VERSION ""
NS_ :

BS_:
BU_: Vector__XXX

BO_ 1296 BAR_Alarm: 8 Vector__XXX
 SG_ BRA_Rack_Num : 0|16@1+ (1.0,0) [0.0|10.0] "R" Vector__XXX
 SG_ BRA_RackNum_Alarm_OC : 16|1@1+ (1.0,0) [0.0|1.0] "F" Vector__XXX
 SG_ BRA_RackNum_Alarm_SOC_OV : 17|1@1+ (1.0,0) [0.0|1.0] "F" Vector__XXX
 SG_ BRA_RackNum_Alarm_SOC_UN : 18|1@1+ (1.0,0) [0.0|1.0] "F" Vector__XXX
 SG_ BRA_RackNum_Alarm_OV : 19|1@1+ (1.0,0) [0.0|1.0] "F" Vector__XXX
 SG_ BRA_RackNum_Alarm_UV : 20|1@1+ (1.0,0) [0.0|1.0] "F" Vector__XXX
 SG_ BRA_RackNum_Alarm_Cell_OV : 21|1@1+ (1.0,0) [0.0|1.0] "F" Vector__XXX
 SG_ BRA_RackNum_Alarm__Cell_UV : 22|1@1+ (1.0,0) [0.0|1.0] "F" Vector__XXX
 SG_ BRA_RackNum_Alarm_Cell_UnBalaV : 23|1@1+ (1.0,0) [0.0|1.0] "F" Vector__XXX
 SG_ BRA_RackNum_Alarm_Discharger_Cell_OT : 24|1@1+ (1.0,0) [0.0|1.0] "F" Vector__XXX
 SG_ BRA_RackNum_Alarm_Charger_Cell_OT : 25|1@1+ (1.0,0) [0.0|1.0] "F" Vector__XXX
 SG_ BRA_RackNum_Alarm_Charger_Cell_UT : 26|1@1+ (1.0,0) [0.0|1.0] "F" Vector__XXX
 SG_ BRA_RackNum_Alarm_Charger_Cell_UT : 27|1@1+ (1.0,0) [0.0|1.0] "F" Vector__XXX
 SG_ BRA_RackNum_Alarm_Cell_UnBalaT : 28|1@1+ (1.0,0) [0.0|1.0] "F" Vector__XXX
 SG_ BRA_RackNum_Alarm_Continuously_OP : 29|1@1+ (1.0,0) [0.0|1.0] "F" Vector__XXX
 SG_ BRA_RackNum_Alarm_Peak_OP : 30|1@1+ (1.0,0) [0.0|1.0] "F" Vector__XXX
 SG_ BRA_RackNum_Fault_OC : 32|1@1+ (1.0,0) [0.0|1.0] "F" Vector__XXX
 SG_ BRA_RackNum_Fault_SOC_OV : 33|1@1+ (1.0,0) [0.0|1.0] "F" Vector__XXX
 SG_ BRA_RackNum_Fault_SOC_UN : 34|1@1+ (1.0,0) [0.0|1.0] "F" Vector__XXX
 SG_ BRA_RackNum_Fault_OV : 35|1@1+ (1.0,0) [0.0|1.0] "F" Vector__XXX
 SG_ BRA_RackNum_Fault_UV : 36|1@1+ (1.0,0) [0.0|1.0] "F" Vector__XXX
 SG_ BRA_RackNum_Fault_Cell_OV : 37|1@1+ (1.0,0) [0.0|1.0] "F" Vector__XXX
 SG_ BRA_RackNum_Fault__Cell_UV : 38|1@1+ (1.0,0) [0.0|1.0] "F" Vector__XXX
 SG_ BRA_RackNum_Fault_Cell_UnBalaV : 39|1@1+ (1.0,0) [0.0|1.0] "F" Vector__XXX
 SG_ BRA_RackNum_Fault_Discharger_Cell_OT : 40|1@1+ (1.0,0) [0.0|1.0] "F" Vector__XXX
 SG_ BRA_RackNum_Fault_Charger_Cell_OT : 41|1@1+ (1.0,0) [0.0|1.0] "F" Vector__XXX
 SG_ BRA_RackNum_Fault_Charger_Cell_UT : 42|1@1+ (1.0,0) [0.0|1.0] "F" Vector__XXX
 SG_ BRA_RackNum_Fault_Charger_Cell_UT : 43|1@1+ (1.0,0) [0.0|1.0] "F" Vector__XXX
 SG_ BRA_RackNum_Fault_Cell_UnBalaT : 44|1@1+ (1.0,0) [0.0|1.0] "F" Vector__XXX
 SG_ BRA_RackNum_Fault_Continuously_OP : 45|1@1+ (1.0,0) [0.0|1.0] "F" Vector__XXX
 SG_ BRA_RackNum_Fault_Peak_OP : 46|1@1+ (1.0,0) [0.0|1.0] "F" Vector__XXX

BO_ 1298 BAR_DIO: 8 Vector__XXX
 SG_ BRA_Rack_Num : 0|16@1+ (1.0,0) [0.0|10.0] "R" Vector__XXX
 SG_ BRA_RackNum_Prelay_DO_Status : 16|1@1+ (1.0,0) [0.0|1.0] "F" Vector__XXX
 SG_ BRA_RackNum_Nrelay_DO_Status : 17|1@1+ (1.0,0) [0.0|1.0] "F" Vector__XXX
 SG_ BRA_RackNum_ProRelay_DO_Status : 18|1@1+ (1.0,0) [0.0|1.0] "F" Vector__XXX
 SG_ BRA_RackNum_PowerLamp_DO_Status : 19|1@1+ (1.0,0) [0.0|1.0] "F" Vector__XXX
 SG_ BRA_RackNum_Buzzer_DO_Status : 20|1@1+ (1.0,0) [0.0|1.0] "F" Vector__XXX
 SG_ BRA_RackNum_PRelayAUX_DI_Status : 32|1@1+ (1.0,0) [0.0|1.0] "F" Vector__XXX
 SG_ BRA_RackNum_NRelayAUX_DI_Status : 33|1@1+ (1.0,0) [0.0|1.0] "F" Vector__XXX
 SG_ BRA_RackNum_EMGSwitch_DI_Status : 34|1@1+ (1.0,0) [0.0|1.0] "F" Vector__XXX
 SG_ BRA_RackNum_MDS_DI_Status : 35|1@1+ (1.0,0) [0.0|1.0] "F" Vector__XXX
 SG_ BRA_RackNum_Waterleak_Dete_MD1 : 48|1@1+ (1.0,0) [0.0|1.0] "F" Vector__XXX
 SG_ BRA_RackNum_Waterleak_Dete_MD2 : 49|1@1+ (1.0,0) [0.0|1.0] "F" Vector__XXX
 SG_ BRA_RackNum_Waterleak_Dete_MD3 : 50|1@1+ (1.0,0) [0.0|1.0] "F" Vector__XXX
 SG_ BRA_RackNum_Waterleak_Dete_MD4 : 51|1@1+ (1.0,0) [0.0|1.0] "F" Vector__XXX
 SG_ BRA_RackNum_Waterleak_Dete_MD5 : 52|1@1+ (1.0,0) [0.0|1.0] "F" Vector__XXX
 SG_ BRA_RackNum_Waterleak_Dete_MD6 : 53|1@1+ (1.0,0) [0.0|1.0] "F" Vector__XXX
 SG_ BRA_RackNum_Waterleak_Dete_MD7 : 54|1@1+ (1.0,0) [0.0|1.0] "F" Vector__XXX

BO_ 1297 BAR_Protect: 8 Vector__XXX
 SG_ BRA_Rack_Num : 0|16@1+ (1.0,0) [0.0|10.0] "R" Vector__XXX
 SG_ BRA_RackNum_Prtct_OC : 16|1@1+ (1.0,0) [0.0|1.0] "F" Vector__XXX
 SG_ BRA_RackNum_Prtct_SOC_OV : 17|1@1+ (1.0,0) [0.0|1.0] "F" Vector__XXX
 SG_ BRA_RackNum_Prtct_SOC_UN : 18|1@1+ (1.0,0) [0.0|1.0] "F" Vector__XXX
 SG_ BRA_RackNum_Prtct_OV : 19|1@1+ (1.0,0) [0.0|1.0] "F" Vector__XXX
 SG_ BRA_RackNum_Prtct_UV : 20|1@1+ (1.0,0) [0.0|1.0] "F" Vector__XXX
 SG_ BRA_RackNum_Prtct_Cell_OV : 21|1@1+ (1.0,0) [0.0|1.0] "F" Vector__XXX
 SG_ BRA_RackNum_Prtct__Cell_UV : 22|1@1+ (1.0,0) [0.0|1.0] "F" Vector__XXX
 SG_ BRA_RackNum_Prtct_Cell_UnBalaV : 23|1@1+ (1.0,0) [0.0|1.0] "F" Vector__XXX
 SG_ BRA_RackNum_Prtct_Discharger_Cell_OT : 24|1@1+ (1.0,0) [0.0|1.0] "F" Vector__XXX
 SG_ BRA_RackNum_Prtct_Charger_Cell_OT : 25|1@1+ (1.0,0) [0.0|1.0] "F" Vector__XXX
 SG_ BRA_RackNum_Prtct_Charger_Cell_UT : 26|1@1+ (1.0,0) [0.0|1.0] "F" Vector__XXX
 SG_ BRA_RackNum_Prtct_Charger_Cell_UT : 27|1@1+ (1.0,0) [0.0|1.0] "F" Vector__XXX
 SG_ BRA_RackNum_Prtct_Cell_UnBalaT : 28|1@1+ (1.0,0) [0.0|1.0] "F" Vector__XXX
 SG_ BRA_RackNum_Prtct_Continuously_OP : 29|1@1+ (1.0,0) [0.0|1.0] "F" Vector__XXX
 SG_ BRA_RackNum_Prtct_Peak_OP : 30|1@1+ (1.0,0) [0.0|1.0] "F" Vector__XXX
 SG_ BRA_RackNum_Prtct_InternalCOM : 31|1@1+ (1.0,0) [0.0|1.0] "F" Vector__XXX
 SG_ BRA_RackNum_Prtct_ExternalCOM : 32|1@1+ (1.0,0) [0.0|1.0] "F" Vector__XXX
 SG_ BRA_RackNum_Prtct_RelayWelding : 33|1@1+ (1.0,0) [0.0|1.0] "F" Vector__XXX
 SG_ BRA_RackNum_Prtct_WaterLeak : 34|1@1+ (1.0,0) [0.0|1.0] "F" Vector__XXX
 SG_ BRA_RackNum_Prtct_InsulationReg : 35|1@1+ (1.0,0) [0.0|1.0] "F" Vector__XXX
 SG_ BRA_RackNum_Prtct_MDSFuse : 36|1@1+ (1.0,0) [0.0|1.0] "F" Vector__XXX
 SG_ BRA_RackNum_Prtct_CoolingSystem : 37|1@1+ (1.0,0) [0.0|1.0] "F" Vector__XXX

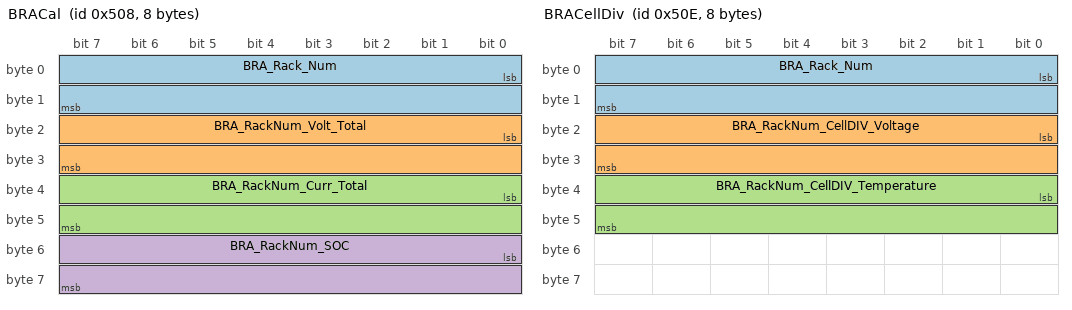
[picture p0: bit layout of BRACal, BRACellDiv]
BO_ 1288 BRACal: 8 Vector__XXX
 SG_ BRA_Rack_Num : 0|16@1+ (1.0,0) [0.0|10.0] "R" Vector__XXX
 SG_ BRA_RackNum_Volt_Total : 16|16@1+ (0.1,0) [400.0|800.0] "V" Vector__XXX
 SG_ BRA_RackNum_Curr_Total : 32|16@1- (0.1,0) [-500.0|500.0] "A" Vector__XXX
 SG_ BRA_RackNum_SOC : 48|16@1+ (0.1,0) [0.0|100.0] "%" Vector__XXX

BO_ 1294 BRACellDiv: 8 Vector__XXX
 SG_ BRA_Rack_Num : 0|16@1+ (1.0,0) [0.0|10.0] "R" Vector__XXX
 SG_ BRA_RackNum_CellDIV_Voltage : 16|16@1+ (1.0,0) [0.0|1000.0] "mV" Vector__XXX
 SG_ BRA_RackNum_CellDIV_Temperature : 32|16@1+ (0.1,0) [0.0|25.0] "℃" Vector__XXX

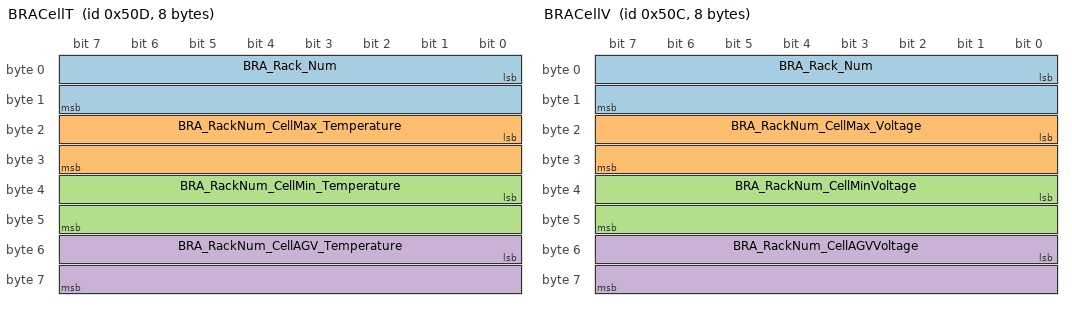
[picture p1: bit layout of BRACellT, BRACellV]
BO_ 1293 BRACellT: 8 Vector__XXX
 SG_ BRA_Rack_Num : 0|16@1+ (1.0,0) [0.0|10.0] "R" Vector__XXX
 SG_ BRA_RackNum_CellMax_Temperature : 16|16@1- (0.1,0) [-40.0|100.0] "℃" Vector__XXX
 SG_ BRA_RackNum_CellMin_Temperature : 32|16@1- (0.1,0) [-40.0|100.0] "℃" Vector__XXX
 SG_ BRA_RackNum_CellAGV_Temperature : 48|16@1- (0.1,0) [-40.0|100.0] "℃" Vector__XXX

BO_ 1292 BRACellV: 8 Vector__XXX
 SG_ BRA_Rack_Num : 0|16@1+ (1.0,0) [0.0|10.0] "R" Vector__XXX
 SG_ BRA_RackNum_CellMax_Voltage : 16|16@1+ (0.001,0) [2.8|4.5] "V" Vector__XXX
 SG_ BRA_RackNum_CellMinVoltage : 32|16@1+ (0.001,0) [2.8|4.5] "V" Vector__XXX
 SG_ BRA_RackNum_CellAGVVoltage : 48|16@1+ (0.001,0) [2.8|4.5] "V" Vector__XXX

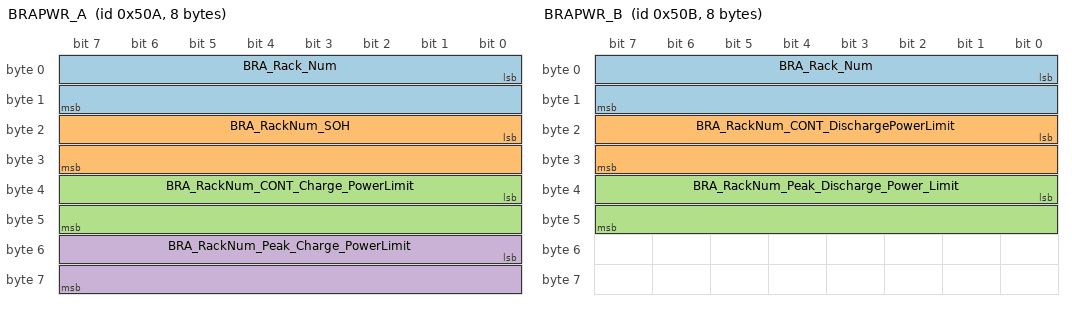
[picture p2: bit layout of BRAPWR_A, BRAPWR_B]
BO_ 1290 BRAPWR_A: 8 Vector__XXX
 SG_ BRA_Rack_Num : 0|16@1+ (1.0,0) [0.0|10.0] "R" Vector__XXX
 SG_ BRA_RackNum_SOH : 16|16@1+ (0.1,0) [0.0|100.0] "%" Vector__XXX
 SG_ BRA_RackNum_CONT_Charge_PowerLimit : 32|16@1+ (0.1,0) [0.0|200.0] "kW" Vector__XXX
 SG_ BRA_RackNum_Peak_Charge_PowerLimit : 48|16@1+ (0.1,0) [0.0|300.0] "kW" Vector__XXX

BO_ 1291 BRAPWR_B: 8 Vector__XXX
 SG_ BRA_Rack_Num : 0|16@1+ (1.0,0) [0.0|10.0] "" Vector__XXX
 SG_ BRA_RackNum_CONT_DischargePowerLimit : 16|16@1+ (0.1,0) [0.0|600.0] "kW" Vector__XXX
 SG_ BRA_RackNum_Peak_Discharge_Power_Limit : 32|16@1+ (0.1,0) [0.0|800.0] "kW" Vector__XXX

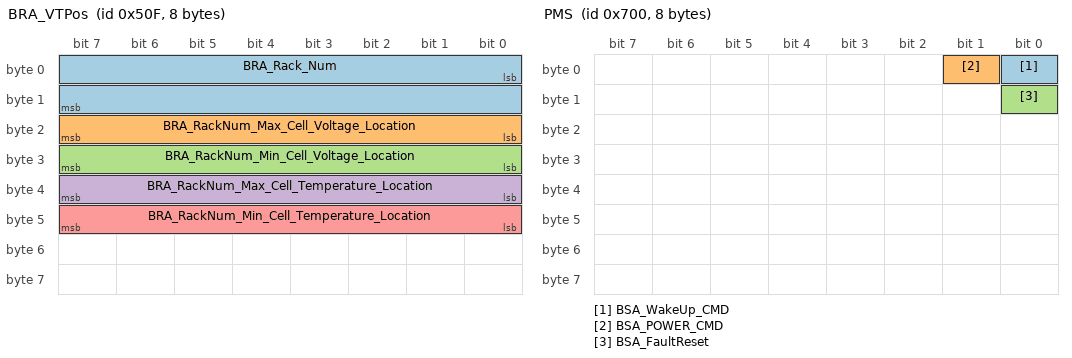
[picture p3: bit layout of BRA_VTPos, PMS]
BO_ 1295 BRA_VTPos: 8 Vector__XXX
 SG_ BRA_Rack_Num : 0|16@1+ (1.0,0) [0.0|10.0] "R" Vector__XXX
 SG_ BRA_RackNum_Max_Cell_Voltage_Location : 16|8@1+ (1.0,0) [0.0|288.0] "C" Vector__XXX
 SG_ BRA_RackNum_Min_Cell_Voltage_Location : 24|8@1+ (1.0,0) [0.0|288.0] "C" Vector__XXX
 SG_ BRA_RackNum_Max_Cell_Temperature_Location : 32|8@1+ (1.0,0) [0.0|288.0] "C" Vector__XXX
 SG_ BRA_RackNum_Min_Cell_Temperature_Location : 40|8@1+ (1.0,0) [0.0|288.0] "C" Vector__XXX

BO_ 1792 PMS: 8 Vector__XXX
 SG_ BSA_WakeUp_CMD : 0|1@1+ (1.0,0) [0.0|1.0] "F" Vector__XXX
 SG_ BSA_POWER_CMD : 1|1@1+ (1.0,0) [0.0|1.0] "F" Vector__XXX
 SG_ BSA_FaultReset : 8|1@1+ (1.0,0) [0.0|1.0] "F" Vector__XXX

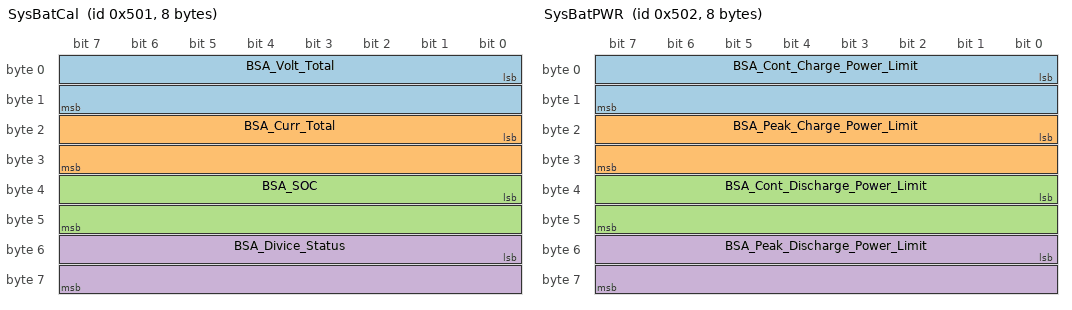
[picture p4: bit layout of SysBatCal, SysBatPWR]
BO_ 1281 SysBatCal: 8 Vector__XXX
 SG_ BSA_Volt_Total : 0|16@1+ (0.1,0) [400.0|800.0] "V" Vector__XXX
 SG_ BSA_Curr_Total : 16|16@1- (0.1,0) [-500.0|500.0] "A" Vector__XXX
 SG_ BSA_SOC : 32|16@1+ (0.1,0) [0.0|100.0] "%" Vector__XXX
 SG_ BSA_Divice_Status : 48|16@1+ (1.0,0) [0.0|10.0] "S" Vector__XXX

BO_ 1287 SysBatDIO: 8 Vector__XXX
 SG_ BSA_Prelay_DO_Status : 0|1@1+ (1.0,0) [0.0|1.0] "F" Vector__XXX
 SG_ BSA_Nrelay_DO_Status : 1|1@1+ (1.0,0) [0.0|1.0] "F" Vector__XXX
 SG_ BSA_ProRelay_DO_Status : 2|1@1+ (1.0,0) [0.0|1.0] "F" Vector__XXX
 SG_ BSA_Buzzer_DO_Status : 3|1@1+ (1.0,0) [0.0|1.0] "F" Vector__XXX
 SG_ BSA_PowerLamp_DO_Status : 4|1@1+ (1.0,0) [0.0|1.0] "F" Vector__XXX
 SG_ BSA_DO_Spare06 : 5|1@1+ (1.0,0) [0.0|1.0] "F" Vector__XXX
 SG_ BSA_DO_Spare07 : 6|1@1+ (1.0,0) [0.0|1.0] "F" Vector__XXX
 SG_ BSA_DO_Spare08 : 7|1@1+ (1.0,0) [0.0|1.0] "F" Vector__XXX
 SG_ BSA_DO_Spare09 : 8|1@1+ (1.0,0) [0.0|1.0] "F" Vector__XXX
 SG_ BSA_DO_Spare10 : 9|1@1+ (1.0,0) [0.0|1.0] "F" Vector__XXX
 SG_ BSA_DO_Spare11 : 10|1@1+ (1.0,0) [0.0|1.0] "F" Vector__XXX
 SG_ BSA_DO_Spare12 : 11|1@1+ (1.0,0) [0.0|1.0] "F" Vector__XXX
 SG_ BSA_PRelayAUX_DI_Status : 12|1@1+ (1.0,0) [0.0|1.0] "F" Vector__XXX
 SG_ BSA_NRelayAUX_DI_Status : 13|1@1+ (1.0,0) [0.0|1.0] "F" Vector__XXX
 SG_ BSA_EMGSwitch_DI_Status : 14|1@1+ (1.0,0) [0.0|1.0] "F" Vector__XXX
 SG_ BSA_CoolingSystem_DI_Status : 15|1@1+ (1.0,0) [0.0|1.0] "F" Vector__XXX
 SG_ BSA_MDS_DI_Status : 16|1@1+ (1.0,0) [0.0|1.0] "F" Vector__XXX
 SG_ BSA_DI_Spare06 : 17|1@1+ (1.0,0) [0.0|1.0] "F" Vector__XXX
 SG_ BSA_DI_Spare07 : 18|1@1+ (1.0,0) [0.0|1.0] "F" Vector__XXX
 SG_ BSA_DI_Spare08 : 19|1@1+ (1.0,0) [0.0|1.0] "F" Vector__XXX
 SG_ BSA_DI_Spare09 : 20|1@1+ (1.0,0) [0.0|1.0] "F" Vector__XXX
 SG_ BSA_DI_Spare10 : 21|1@1+ (1.0,0) [0.0|1.0] "F" Vector__XXX
 SG_ BSA_DI_Spare11 : 22|1@1+ (1.0,0) [0.0|1.0] "F" Vector__XXX
 SG_ BSA_DI_Spare12 : 23|1@1+ (1.0,0) [0.0|1.0] "F" Vector__XXX

BO_ 1287 SysBatDIO: 8 Vector__XXX
 SG_ BSA_SOH : 48|16@1+ (0.1,0) [0.0|100.0] "%" Vector__XXX

BO_ 1282 SysBatPWR: 8 Vector__XXX
 SG_ BSA_Cont_Charge_Power_Limit : 0|16@1+ (0.1,0) [0.0|200.0] "kW" Vector__XXX
 SG_ BSA_Peak_Charge_Power_Limit : 16|16@1+ (0.1,0) [0.0|300.0] "kW" Vector__XXX
 SG_ BSA_Cont_Discharge_Power_Limit : 32|16@1+ (0.1,0) [0.0|600.0] "kW" Vector__XXX
 SG_ BSA_Peak_Discharge_Power_Limit : 48|16@1+ (0.1,0) [0.0|800.0] "kW" Vector__XXX

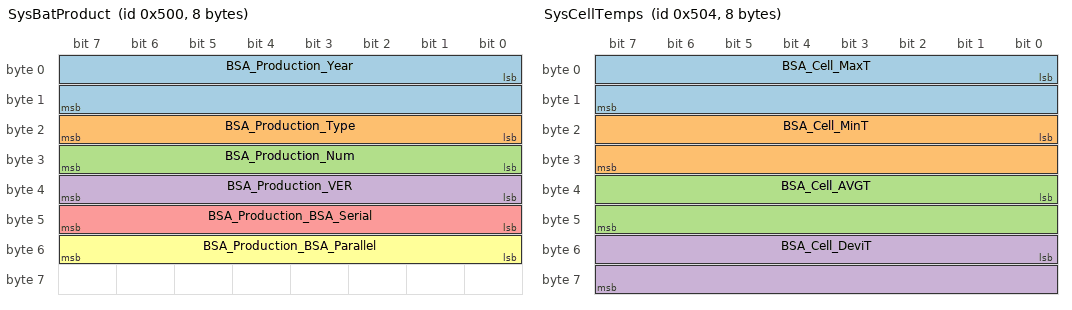
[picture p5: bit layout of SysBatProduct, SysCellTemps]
BO_ 1280 SysBatProduct: 8 Vector__XXX
 SG_ BSA_Production_Year : 0|16@1+ (1.0,0) [2000.0|2050.0] "Year" Vector__XXX
 SG_ BSA_Production_Type : 16|8@1+ (1.0,0) [0.0|20.0] "Type" Vector__XXX
 SG_ BSA_Production_Num : 24|8@1+ (1.0,0) [0.0|255.0] "Num" Vector__XXX
 SG_ BSA_Production_VER : 32|8@1+ (0.1,0) [0.0|25.0] "Ver" Vector__XXX
 SG_ BSA_Production_BSA_Serial : 40|8@1+ (1.0,0) [0.0|288.0] "S" Vector__XXX
 SG_ BSA_Production_BSA_Parallel : 48|8@1+ (1.0,0) [0.0|10.0] "P" Vector__XXX

BO_ 1286 SysBatProtect: 8 Vector__XXX
 SG_ BSA_Alarm_OC : 0|1@1+ (1.0,0) [0.0|1.0] "F" Vector__XXX
 SG_ BSA_Alarm_SOC_OV : 1|1@1+ (1.0,0) [0.0|1.0] "F" Vector__XXX
 SG_ BSA_Alarm_SOC_UN : 2|1@1+ (1.0,0) [0.0|1.0] "F" Vector__XXX
 SG_ BSA_Alarm_OV : 3|1@1+ (1.0,0) [0.0|1.0] "F" Vector__XXX
 SG_ BSA_Alarm_UV : 4|1@1+ (1.0,0) [0.0|1.0] "F" Vector__XXX
 SG_ BSA_Alarm_Cell_OV : 5|1@1+ (1.0,0) [0.0|1.0] "F" Vector__XXX
 SG_ BSA_Alarm__Cell_UV : 6|1@1+ (1.0,0) [0.0|1.0] "F" Vector__XXX
 SG_ BSA_Alarm_Cell_UnBalaV : 7|1@1+ (1.0,0) [0.0|1.0] "F" Vector__XXX
 SG_ BSA_Alarm_Discharger_Cell_OT : 8|1@1+ (1.0,0) [0.0|1.0] "F" Vector__XXX
 SG_ BSA_Alarm_Charger_Cell_OT : 9|1@1+ (1.0,0) [0.0|1.0] "F" Vector__XXX
 SG_ BSA_Alarm_Charger_Cell_UT : 10|1@1+ (1.0,0) [0.0|1.0] "F" Vector__XXX
 SG_ BSA_Alarm_Charger_Cell_UT : 11|1@1+ (1.0,0) [0.0|1.0] "F" Vector__XXX
 SG_ BSA_Alarm_Cell_UnBalaT : 12|1@1+ (1.0,0) [0.0|1.0] "F" Vector__XXX
 SG_ BSA_Alarm_Continuously_OP : 13|1@1+ (1.0,0) [0.0|1.0] "F" Vector__XXX
 SG_ BSA_Alarm_Peak_OP : 14|1@1+ (1.0,0) [0.0|1.0] "F" Vector__XXX
 SG_ BSA_Fault_OC : 16|1@1+ (1.0,0) [0.0|1.0] "F" Vector__XXX
 SG_ BSA_Fault_SOC_OV : 17|1@1+ (1.0,0) [0.0|1.0] "F" Vector__XXX
 SG_ BSA_Fault_SOC_UN : 18|1@1+ (1.0,0) [0.0|1.0] "F" Vector__XXX
 SG_ BSA_Fault_OV : 19|1@1+ (1.0,0) [0.0|1.0] "F" Vector__XXX
 SG_ BSA_Fault_UV : 20|1@1+ (1.0,0) [0.0|1.0] "F" Vector__XXX
 SG_ BSA_Fault_Cell_OV : 21|1@1+ (1.0,0) [0.0|1.0] "F" Vector__XXX
 SG_ BSA_Fault__Cell_UV : 22|1@1+ (1.0,0) [0.0|1.0] "F" Vector__XXX
 SG_ BSA_Fault_Cell_UnBalaV : 23|1@1+ (1.0,0) [0.0|1.0] "F" Vector__XXX
 SG_ BSA_Fault_Discharger_Cell_OT : 24|1@1+ (1.0,0) [0.0|1.0] "F" Vector__XXX
 SG_ BSA_Fault_Charger_Cell_OT : 25|1@1+ (1.0,0) [0.0|1.0] "F" Vector__XXX
 SG_ BSA_Fault_Charger_Cell_UT : 26|1@1+ (1.0,0) [0.0|1.0] "F" Vector__XXX
 SG_ BSA_Fault_Charger_Cell_UT : 27|1@1+ (1.0,0) [0.0|1.0] "F" Vector__XXX
 SG_ BSA_Fault_Cell_UnBalaT : 28|1@1+ (1.0,0) [0.0|1.0] "F" Vector__XXX
 SG_ BSA_Fault_Continuously_OP : 29|1@1+ (1.0,0) [0.0|1.0] "F" Vector__XXX
 SG_ BSA_Fault_Peak_OP : 30|1@1+ (1.0,0) [0.0|1.0] "F" Vector__XXX
 SG_ BSA_Prtct_OC : 32|1@1+ (1.0,0) [0.0|1.0] "F" Vector__XXX
 SG_ BSA_Prtct_SOC_OV : 33|1@1+ (1.0,0) [0.0|1.0] "F" Vector__XXX
 SG_ BSA_Prtct_SOC_UN : 34|1@1+ (1.0,0) [0.0|1.0] "F" Vector__XXX
 SG_ BSA_Prtct_OV : 35|1@1+ (1.0,0) [0.0|1.0] "F" Vector__XXX
 SG_ BSA_Prtct_UV : 36|1@1+ (1.0,0) [0.0|1.0] "F" Vector__XXX
 SG_ BSA_Prtct_Cell_OV : 37|1@1+ (1.0,0) [0.0|1.0] "F" Vector__XXX
 SG_ BSA_Prtct__Cell_UV : 38|1@1+ (1.0,0) [0.0|1.0] "F" Vector__XXX
 SG_ BSA_Prtct_Cell_UnBalaV : 39|1@1+ (1.0,0) [0.0|1.0] "F" Vector__XXX
 SG_ BSA_Prtct_Discharger_Cell_OT : 40|1@1+ (1.0,0) [0.0|1.0] "F" Vector__XXX
 SG_ BSA_Prtct_Charger_Cell_OT : 41|1@1+ (1.0,0) [0.0|1.0] "F" Vector__XXX
 SG_ BSA_Prtct_Charger_Cell_UT : 42|1@1+ (1.0,0) [0.0|1.0] "F" Vector__XXX
 SG_ BSA_Prtct_Charger_Cell_UT : 43|1@1+ (1.0,0) [0.0|1.0] "F" Vector__XXX
 SG_ BSA_Prtct_Cell_UnBalaT : 44|1@1+ (1.0,0) [0.0|1.0] "F" Vector__XXX
 SG_ BSA_Prtct_Continuously_OP : 45|1@1+ (1.0,0) [0.0|1.0] "F" Vector__XXX
 SG_ BSA_Prtct_Peak_OP : 46|1@1+ (1.0,0) [0.0|1.0] "F" Vector__XXX
 SG_ BSA_Prtct_InternalCOM : 47|1@1+ (1.0,0) [0.0|1.0] "F" Vector__XXX
 SG_ BSA_Prtct_ExternalCOM : 48|1@1+ (1.0,0) [0.0|1.0] "F" Vector__XXX
 SG_ BSA_Prtct_RelayWelding : 49|1@1+ (1.0,0) [0.0|1.0] "F" Vector__XXX
 SG_ BSA_Prtct_WaterLeak : 50|1@1+ (1.0,0) [0.0|1.0] "F" Vector__XXX
 SG_ BSA_Prtct_InsulationReg : 51|1@1+ (1.0,0) [0.0|1.0] "F" Vector__XXX
 SG_ BSA_Prtct_MDSFuse : 52|1@1+ (1.0,0) [0.0|1.0] "F" Vector__XXX
 SG_ BSA_Prtct_Cooling_System : 53|1@1+ (1.0,0) [0.0|1.0] "F" Vector__XXX

BO_ 1284 SysCellTemps: 8 Vector__XXX
 SG_ BSA_Cell_MaxT : 0|16@1- (0.1,0) [-40.0|100.0] "℃" Vector__XXX
 SG_ BSA_Cell_MinT : 16|16@1- (0.1,0) [-40.0|100.0] "℃" Vector__XXX
 SG_ BSA_Cell_AVGT : 32|16@1- (0.1,0) [-40.0|100.0] "℃" Vector__XXX
 SG_ BSA_Cell_DeviT : 48|16@1+ (0.1,0) [0.0|25.0] "℃" Vector__XXX

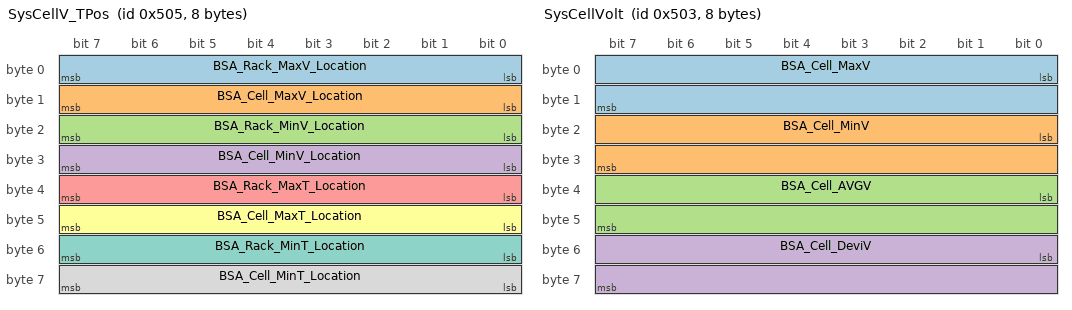
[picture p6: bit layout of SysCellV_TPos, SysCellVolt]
BO_ 1285 SysCellV_TPos: 8 Vector__XXX
 SG_ BSA_Rack_MaxV_Location : 0|8@1+ (1.0,0) [1.0|10.0] "R" Vector__XXX
 SG_ BSA_Cell_MaxV_Location : 8|8@1+ (1.0,0) [1.0|288.0] "C" Vector__XXX
 SG_ BSA_Rack_MinV_Location : 16|8@1+ (1.0,0) [1.0|10.0] "R" Vector__XXX
 SG_ BSA_Cell_MinV_Location : 24|8@1+ (1.0,0) [1.0|288.0] "C" Vector__XXX
 SG_ BSA_Rack_MaxT_Location : 32|8@1+ (1.0,0) [1.0|10.0] "R" Vector__XXX
 SG_ BSA_Cell_MaxT_Location : 40|8@1+ (1.0,0) [1.0|288.0] "C" Vector__XXX
 SG_ BSA_Rack_MinT_Location : 48|8@1+ (1.0,0) [1.0|10.0] "R" Vector__XXX
 SG_ BSA_Cell_MinT_Location : 56|8@1+ (1.0,0) [1.0|288.0] "C" Vector__XXX

BO_ 1283 SysCellVolt: 8 Vector__XXX
 SG_ BSA_Cell_MaxV : 0|16@1+ (0.001,0) [2.8|4.5] "V" Vector__XXX
 SG_ BSA_Cell_MinV : 16|16@1+ (0.001,0) [2.8|4.5] "V" Vector__XXX
 SG_ BSA_Cell_AVGV : 32|16@1+ (0.001,0) [2.8|4.5] "V" Vector__XXX
 SG_ BSA_Cell_DeviV : 48|16@1+ (1.0,0) [0.0|1000.0] "mV" Vector__XXX
